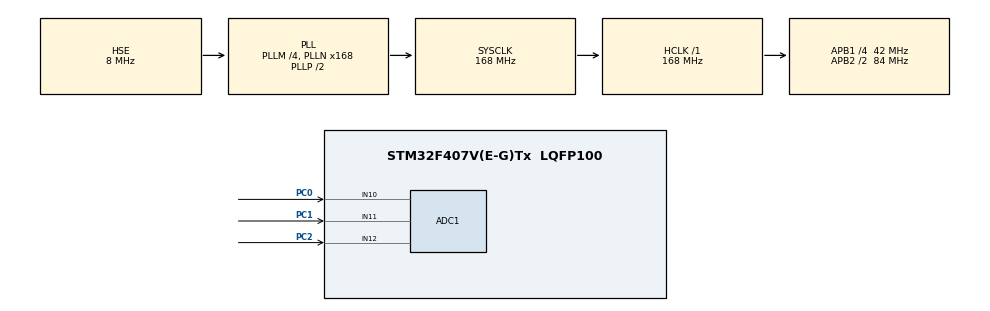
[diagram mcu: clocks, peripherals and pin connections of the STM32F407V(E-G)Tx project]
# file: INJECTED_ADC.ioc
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ADC1.Channel-0\#ChannelRegularConversion=ADC_CHANNEL_10
ADC1.Channel-1\#ChannelInjectedConversion=ADC_CHANNEL_10
ADC1.Channel-2\#ChannelInjectedConversion=ADC_CHANNEL_11
ADC1.Channel-3\#ChannelInjectedConversion=ADC_CHANNEL_12
ADC1.InjNumberOfConversion=3
ADC1.InjectedOffset-1\#ChannelInjectedConversion=0
ADC1.InjectedOffset-2\#ChannelInjectedConversion=0
ADC1.InjectedOffset-3\#ChannelInjectedConversion=0
ADC1.InjectedRank-1\#ChannelInjectedConversion=1
ADC1.InjectedRank-2\#ChannelInjectedConversion=2
ADC1.InjectedRank-3\#ChannelInjectedConversion=3
ADC1.NbrOfConversionFlag=1
ADC1.Rank-0\#ChannelRegularConversion=1
ADC1.SamplingTime-0\#ChannelRegularConversion=ADC_SAMPLETIME_3CYCLES
ADC1.SamplingTime-1\#ChannelInjectedConversion=ADC_SAMPLETIME_112CYCLES
ADC1.SamplingTime-2\#ChannelInjectedConversion=ADC_SAMPLETIME_112CYCLES
ADC1.SamplingTime-3\#ChannelInjectedConversion=ADC_SAMPLETIME_112CYCLES
ADC1.ScanConvMode=ENABLE
ADC1.master=1
Mcu.Family=STM32F4
Mcu.Name=STM32F407V(E-G)Tx
Mcu.Package=LQFP100
NVIC.ADC_IRQn=true\:0\:0\:false\:false\:true\:true\:true\:true
NVIC.PriorityGroup=NVIC_PRIORITYGROUP_4
PA13.Mode=Serial_Wire
PA13.Signal=SYS_JTMS-SWDIO
PA14.Mode=Serial_Wire
PA14.Signal=SYS_JTCK-SWCLK
PC0.Signal=ADCx_IN10
PC1.Signal=ADCx_IN11
PC2.Signal=ADCx_IN12
PH0-OSC_IN.Mode=HSE-External-Oscillator
PH0-OSC_IN.Signal=RCC_OSC_IN
PH1-OSC_OUT.Mode=HSE-External-Oscillator
PH1-OSC_OUT.Signal=RCC_OSC_OUT
ProjectManager.HeapSize=0x200
ProjectManager.StackSize=0x400
ProjectManager.TargetToolchain=STM32CubeIDE
RCC.48MHZClocksFreq_Value=84000000
RCC.AHBFreq_Value=168000000
RCC.APB1CLKDivider=RCC_HCLK_DIV4
RCC.APB1Freq_Value=42000000
RCC.APB1TimFreq_Value=84000000
RCC.APB2CLKDivider=RCC_HCLK_DIV2
RCC.APB2Freq_Value=84000000
RCC.APB2TimFreq_Value=168000000
RCC.CortexFreq_Value=168000000
RCC.HCLKFreq_Value=168000000
RCC.HSE_VALUE=8000000
RCC.HSI_VALUE=16000000
RCC.LSE_VALUE=32768
RCC.PLLM=4
RCC.PLLN=168
RCC.PLLSourceVirtual=RCC_PLLSOURCE_HSE
RCC.SYSCLKFreq_VALUE=168000000
RCC.SYSCLKSource=RCC_SYSCLKSOURCE_PLLCLK
RCC.VCOOutputFreq_Value=336000000
SH.ADCx_IN10.0=ADC1_IN10,IN10
SH.ADCx_IN11.0=ADC1_IN11,IN11
SH.ADCx_IN12.0=ADC1_IN12,IN12
board=custom

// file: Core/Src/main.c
/* USER CODE BEGIN Header */
/**
  ******************************************************************************
  * @file           : main.c
  * @brief          : Main program body
  ******************************************************************************
  * @attention
  *
  * Copyright (c) 2024 STMicroelectronics.
  * All rights reserved.
  *
  * This software is licensed under terms that can be found in the LICENSE file
  * in the root directory of this software component.
  * If no LICENSE file comes with this software, it is provided AS-IS.
  *
  ******************************************************************************
  */
/* USER CODE END Header */
#include "main.h"
#include "adc.h"
#include "gpio.h"

void SystemClock_Config(void);

int main(void)
{

  /* MCU Configuration--------------------------------------------------------*/

  /* Reset of all peripherals, Initializes the Flash interface and the Systick. */
  HAL_Init();

  /* Configure the system clock */
  SystemClock_Config();

  /* Initialize all configured peripherals */
  MX_GPIO_Init();
  MX_ADC1_Init();

  /* Infinite loop */
  /* USER CODE BEGIN WHILE */
  while (1)
  {
	  /*ADC1 birimini interrupt modu ile birlikte başlatabilmek için HAL_ADCEx_InjectedStart_IT fonksiyonu
	  main içerisindeki sonsuz döngü içerisinde çağrılır, istenen gecikme ile çevrim tekarlanır*/

	  //ADC1 birimi injected grup çevrimi startı aktifleştirilerek interrupt modu başlatıldı
	  HAL_ADCEx_InjectedStart_IT(&hadc1);
	  HAL_Delay(1000);
    /* USER CODE END WHILE */

  }
}

void SystemClock_Config(void)
{
  RCC_OscInitTypeDef RCC_OscInitStruct = {0};
  RCC_ClkInitTypeDef RCC_ClkInitStruct = {0};

  /** Configure the main internal regulator output voltage
  */
  __HAL_RCC_PWR_CLK_ENABLE();
  __HAL_PWR_VOLTAGESCALING_CONFIG(PWR_REGULATOR_VOLTAGE_SCALE1);

  /** Initializes the RCC Oscillators according to the specified parameters
  * in the RCC_OscInitTypeDef structure.
  */
  RCC_OscInitStruct.OscillatorType = RCC_OSCILLATORTYPE_HSE;
  RCC_OscInitStruct.HSEState = RCC_HSE_ON;
  RCC_OscInitStruct.PLL.PLLState = RCC_PLL_ON;
  RCC_OscInitStruct.PLL.PLLSource = RCC_PLLSOURCE_HSE;
  RCC_OscInitStruct.PLL.PLLM = 4;
  RCC_OscInitStruct.PLL.PLLN = 168;
  RCC_OscInitStruct.PLL.PLLP = RCC_PLLP_DIV2;
  RCC_OscInitStruct.PLL.PLLQ = 4;
  if (HAL_RCC_OscConfig(&RCC_OscInitStruct) != HAL_OK)
  {
    Error_Handler();
  }

  /** Initializes the CPU, AHB and APB buses clocks
  */
  RCC_ClkInitStruct.ClockType = RCC_CLOCKTYPE_HCLK|RCC_CLOCKTYPE_SYSCLK
                              |RCC_CLOCKTYPE_PCLK1|RCC_CLOCKTYPE_PCLK2;
  RCC_ClkInitStruct.SYSCLKSource = RCC_SYSCLKSOURCE_PLLCLK;
  RCC_ClkInitStruct.AHBCLKDivider = RCC_SYSCLK_DIV1;
  RCC_ClkInitStruct.APB1CLKDivider = RCC_HCLK_DIV4;
  RCC_ClkInitStruct.APB2CLKDivider = RCC_HCLK_DIV2;

  if (HAL_RCC_ClockConfig(&RCC_ClkInitStruct, FLASH_LATENCY_5) != HAL_OK)
  {
    Error_Handler();
  }
}

void Error_Handler(void)
{
  __disable_irq();
  while (1)
  {
  }
}
